# CANFD register map
Vendor: Texas Instruments
Registers are 32-bit, access per field, reset 0x0 unless marked. A register's access mark holds for its fields unless they carry their own. Offsets are as the file gives them; [hi:lo] are bit positions; lines under a group give offsets from that group; {n}, {i} and the like mark numbered series; 'fields as' and 'values as' point back to an identical list.

## CANFD (part 2 of 2) — IPXACT generated on 6/2/2017 at 11:21 by the IPXCEL-to-IPXACT Converter Script v3.1
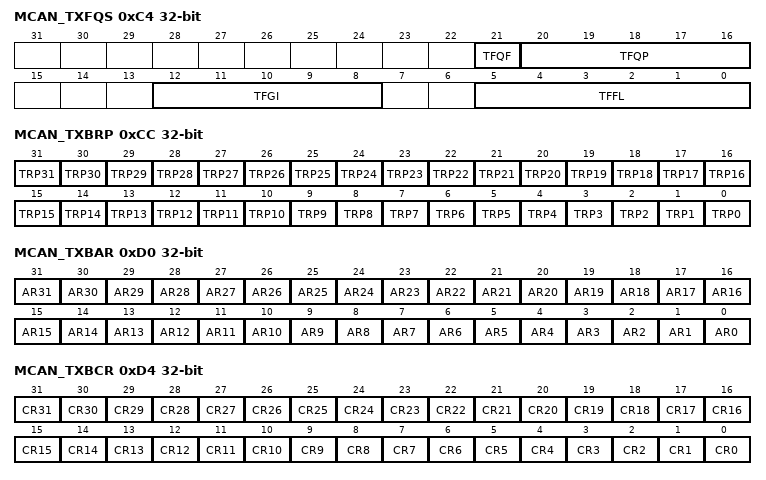
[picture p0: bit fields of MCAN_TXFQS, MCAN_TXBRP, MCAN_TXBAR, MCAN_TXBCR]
0xC4 MCAN_TXFQS ro — The Tx FIFO/Queue status is related to the pending Tx requests listed in register TXBRP. Therefore the effect of Add/Cancellation requests may be delayed due to a running Tx scan (TXBRP not yet updated).
  [21] TFQF — Tx FIFO/Queue Full 0 Tx FIFO/Queue not full 1 Tx FIFO/Queue full
  [20:16] TFQP — Tx FIFO/Queue Put Index. Tx FIFO/Queue write index pointer, range 0 to 31. Note: In case of mixed configurations where dedicated Tx Buffers are combined with a Tx FIFO or a Tx Queue, the Put and Get Indices indicate the number of the Tx Buffer starting with the first dedicated Tx Buffers. Example: For a configuration of 12 dedicated Tx Buffers and a Tx FIFO of 20 Buffers a Put Index of 15 points to the fourth buffer of the Tx FIFO.
  [12:8] TFGI — Tx FIFO Get Index. Tx FIFO read index pointer, range 0 to 31. Read as zero when Tx Queue operation is configured (TXBC.TFQM = '1'). Note: In case of mixed configurations where dedicated Tx Buffers are combined with a Tx FIFO or a Tx Queue, the Put and Get Indices indicate the number of the Tx Buffer starting with the first dedicated Tx Buffers. Example: For a configuration of 12 dedicated Tx Buffers and a Tx FIFO of 20 Buffers a Put Index of 15 points to the fourth buffer of the Tx FIFO.
  [5:0] TFFL — Tx FIFO Free Level. Number of consecutive free Tx FIFO elements starting from TFGI, range 0 to 32. Read as zero when Tx Queue operation is configured (TXBC.TFQM = '1').
0xC8 MCAN_TXESC — Configures the number of data bytes belonging to a Tx Buffer element. Data field sizes $gt; 8 bytes are intended for CAN FD operation only.
  [2:0] TBDS rw — Tx Buffer Data Field Size 000 8 byte data field 001 12 byte data field 010 16 byte data field 011 20 byte data field 100 24 byte data field 101 32 byte data field 110 48 byte data field 111 64 byte data field Note: In case the data length code DLC of a Tx Buffer element is configured to a value higher than the Tx Buffer data field size TXESC.TBDS, the bytes not defined by the Tx Buffer are transmitted as "0xCC" (padding bytes). Qualified Write is possible only with CCCR.CCE='1' and CCCR.INIT='1'.
0xCC MCAN_TXBRP ro — MCAN Tx Buffer Request Pending
  [n] TRP{n} (n=1..31) — Transmission Request Pending {n}. See description for bit 0.
  [0] TRP0 — Transmission Request Pending 0. Each Tx Buffer has its own Transmission Request Pending bit. The bits are set via register TXBAR. The bits are reset after a requested transmission has completed or has been cancelled via register TXBCR. TXBRP bits are set only for those Tx Buffers configured via TXBC. After a TXBRP bit has been set, a Tx scan is started to check for the pending Tx request with the highest priority (Tx Buffer with lowest Message ID). A cancellation request resets the corresponding transmission request pending bit of register TXBRP. In case a transmission has already been started when a cancellation is requested, this is done at the end of the transmission, regardless whether the transmission was successful or not. The cancellation request bits are reset directly after the corresponding TXBRP bit has been reset. After a cancellation has been requested, a finished cancellation is signalled via TXBCF - after successful transmission together with the corresponding TXBTO bit - when the transmission has not yet been started at the point of cancellation - when the transmission has been aborted due to lost arbitration - when an error occurred during frame transmission In DAR mode all transmissions are automatically cancelled if they are not successful. The corresponding TXBCF bit is set for all unsuccessful transmissions. 0 No transmission request pending 1 Transmission request pending Note: TXBRP bits which are set while a Tx scan is in progress are not considered during this particular Tx scan. In case a cancellation is requested for such a Tx Buffer, this Add Request is cancelled immediately, the corresponding TXBRP bit is reset.
0xD0 MCAN_TXBAR rw — MCAN Tx Buffer Add Request
  [n] AR{n} (n=1..31) — Add Request {n}. See description for bit 0.
  [0] AR0 — Add Request 0. Each Tx Buffer has its own Add Request bit. Writing a '1' will set the corresponding Add Request bit; writing a '0' has no impact. This enables the Host to set transmission requests for multiple Tx Buffers with one write to TXBAR. TXBAR bits are set only for those Tx Buffers configured via TXBC. When no Tx scan is running, the bits are reset immediately, else the bits remain set until the Tx scan process has completed. 0 No transmission request added 1 Transmission requested added Note: If an add request is applied for a Tx Buffer with pending transmission request (corresponding TXBRP bit already set), this add request is ignored. Qualified Write is possible only with CCCR.CCE='0'
0xD4 MCAN_TXBCR rw — MCAN Tx Buffer Cancellation Request
  [n] CR{n} (n=1..31) — Cancellation Request {n}. See description for bit 0.
  [0] CR0 — Cancellation Request 0. Each Tx Buffer has its own Cancellation Request bit. Writing a '1' will set the corresponding Cancellation Request bit; writing a '0' has no impact. This enables the Host to set cancellation requests for multiple Tx Buffers with one write to TXBCR. TXBCR bits are set only for those Tx Buffers configured via TXBC. The bits remain set until the corresponding bit of TXBRP is reset. 0 No cancellation pending 1 Cancellation pending Qualified Write is possible only with CCCR.CCE='0'
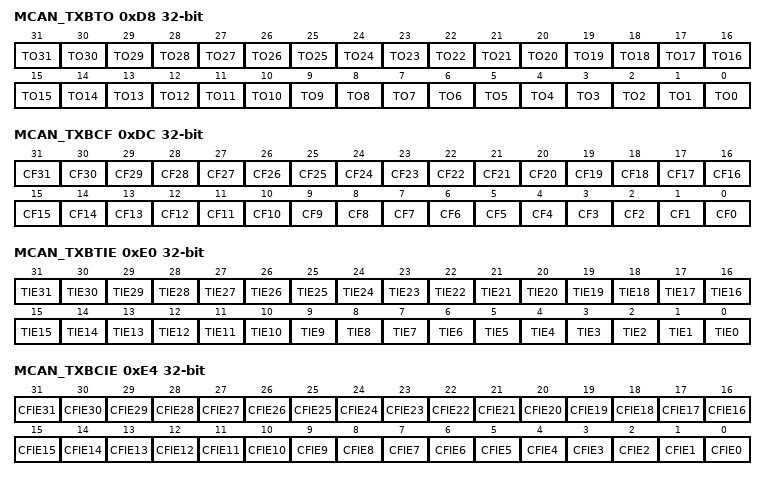
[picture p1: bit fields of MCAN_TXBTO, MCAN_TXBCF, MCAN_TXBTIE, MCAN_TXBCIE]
0xD8 MCAN_TXBTO ro — MCAN Tx Buffer Transmission Occurred
  [n] TO{n} (n=1..31) — Transmission Occurred {n}. See description for bit 0.
  [0] TO0 — Transmission Occurred 0. Each Tx Buffer has its own Transmission Occurred bit. The bits are set when the corresponding TXBRP bit is cleared after a successful transmission. The bits are reset when a new transmission is requested by writing a '1' to the corresponding bit of register TXBAR. 0 No transmission occurred 1 Transmission occurred
0xDC MCAN_TXBCF ro — MCAN Tx Buffer Cancellation Finished
  [n] CF{n} (n=1..31) — Cancellation Finished {n}. See description for bit 0.
  [0] CF0 — Cancellation Finished 0. Each Tx Buffer has its own Cancellation Finished bit. The bits are set when the corresponding TXBRP bit is cleared after a cancellation was requested via TXBCR. In case the corresponding TXBRP bit was not set at the point of cancellation, CF is set immediately. The bits are reset when a new transmission is requested by writing a '1' to the corresponding bit of register TXBAR. 0 No transmit buffer cancellation 1 Transmit buffer cancellation finished
0xE0 MCAN_TXBTIE rw — MCAN Tx Buffer Transmission Interrupt Enable
  [n] TIE{n} (n=0..31) — Transmission Interrupt Enable {n}. Each Tx Buffer has its own Transmission Interrupt Enable bit. 0 Transmission interrupt disabled 1 Transmission interrupt enable
0xE4 MCAN_TXBCIE rw — MCAN Tx Buffer Cancellation Finished Interrupt Enable
  [n] CFIE{n} (n=0..31) — Cancellation Finished Interrupt Enable {n}. Each Tx Buffer has its own Cancellation Finished Interrupt Enable bit. 0 Cancellation finished interrupt disabled 1 Cancellation finished interrupt enabled
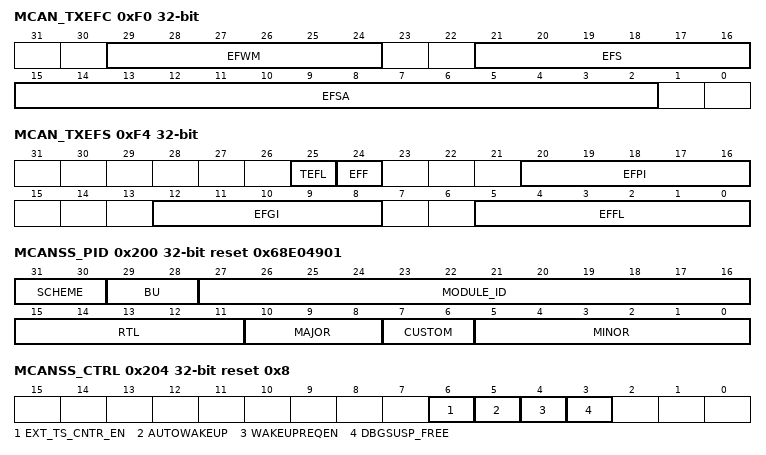
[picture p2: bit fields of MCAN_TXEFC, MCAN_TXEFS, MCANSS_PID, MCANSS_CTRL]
0xF0 MCAN_TXEFC — MCAN Tx Event FIFO Configuration
  [29:24] EFWM rw — Event FIFO Watermark 0 Watermark interrupt disabled 1-32 Level for Tx Event FIFO watermark interrupt (IR.TEFW) $gt;32 Watermark interrupt disabled
  [21:16] EFS rw — Event FIFO Size. The Tx Event FIFO elements are indexed from 0 to EFS - 1. 0 Tx Event FIFO disabled 1-32 Number of Tx Event FIFO elements $gt;32 Values greater than 32 are interpreted as 32
  [15:2] EFSA rw — Event FIFO Start Address. Start address of Tx Event FIFO in Message RAM (32-bit word address).
0xF4 MCAN_TXEFS ro — MCAN Tx Event FIFO Status
  [25] TEFL — Tx Event FIFO Element Lost. This bit is a copy of interrupt flag IR.TEFL. When IR.TEFL is reset, this bit is also reset. 0 No Tx Event FIFO element lost 1 Tx Event FIFO element lost, also set after write attempt to Tx Event FIFO of size zero.
  [24] EFF — Event FIFO Full 0 Tx Event FIFO not full 1 Tx Event FIFO full
  [20:16] EFPI — Event FIFO Put Index.Tx Event FIFO write index pointer, range 0 to 31.
  [12:8] EFGI — Event FIFO Get Index. Tx Event FIFO read index pointer, range 0 to 31.
  [5:0] EFFL — Event FIFO Fill Level. Number of elements stored in Tx Event FIFO, range 0 to 32.
0xF8 MCAN_TXEFA — MCAN Tx Event FIFO Acknowledge
  [4:0] EFAI rw — Event FIFO Acknowledge Index. After the Host has read an element or a sequence of elements from the Tx Event FIFO it has to write the index of the last element read from Tx Event FIFO to EFAI. This will set the Tx Event FIFO Get Index TXEFS.EFGI to EFAI + 1 and update the Event FIFO Fill Level TXEFS.EFFL.
0x200 MCANSS_PID ro reset 0x68E04901 — MCAN Subsystem Revision Register
  [31:30] SCHEME — PID Register Scheme
  [29:28] BU — Business Unit: 0x2 = Processors
  [27:16] MODULE_ID — Module Identification Number
  [15:11] RTL — RTL revision. Will vary depending on release
  [10:8] MAJOR — Major Revision of the MCAN Subsystem
  [7:6] CUSTOM — Custom Value
  [5:0] MINOR — Minor Revision of the MCAN Subsystem
0x204 MCANSS_CTRL reset 0x8 — MCAN Subsystem Control Register
  [6] EXT_TS_CNTR_EN rw — External Timestamp Counter Enable. When disabled, the counter is reset back to zero.While enabled, the counter keeps incrementing. 0 External timestamp counter disabled 1 External timestamp counter enabled
  [5] AUTOWAKEUP rw — Automatic Wakeup Enable. Enables the MCANSS to automatically clear the MCAN CCCR.INIT bit, fully waking the MCAN up, on an enabled wakeup request. 0 Disable the automatic write to CCCR.INIT 1 Enable the automatic write to CCCR.INIT
  [4] WAKEUPREQEN rw — Wakeup Request Enable. Enables the MCANSS to wakeup on CAN RXD activity. 0 Disable wakeup request 1 Enables wakeup request
  [3] DBGSUSP_FREE rw — Debug Suspend Free Bit. Enables debug suspend. 0 Disable debug suspend 1 Enable debug suspend
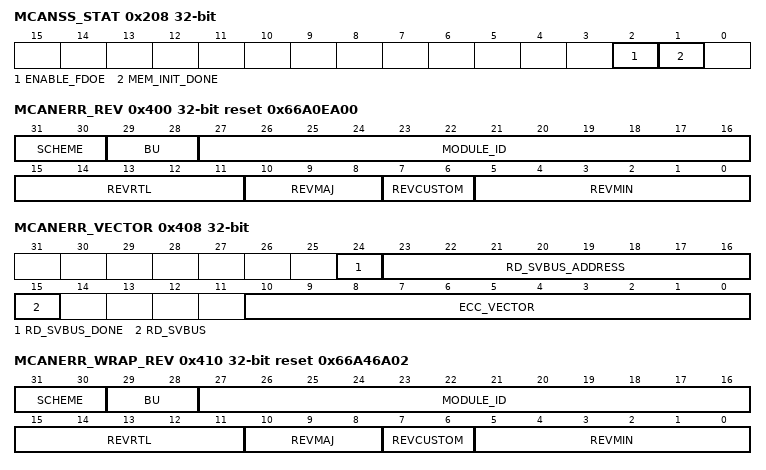
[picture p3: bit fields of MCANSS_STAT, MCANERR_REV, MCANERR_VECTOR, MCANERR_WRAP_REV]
0x208 MCANSS_STAT ro — MCAN Subsystem Status Register
  [2] ENABLE_FDOE — Flexible Datarate Operation Enable. Determines whether CAN FD operation can be enabled via the MCAN core CCCR.FDOE bit (bit 8) or if only standard CAN operation is possible with this instance of the MCAN. 0 MCAN is only capable of standard CAN communication 1 MCAN may be configured to perform CAN FD communication
  [1] MEM_INIT_DONE — Memory Initialization Done. 0 Message RAM initialization is in progress 1 Message RAM is initialized for use
0x20C MCANSS_ICS — MCAN Subsystem Interrupt Clear Shadow Register
  [0] EXT_TS_CNTR_OVFL wo — External Timestamp Counter Overflow Interrupt Status Clear. Reads always return a 0. 0 Write of '0' has no effect 1 Write of '1' clears the MCANSS_IRS.EXT_TS_CNTR_OVFL bit
0x210 MCANSS_IRS — MCAN Subsystem Interrupt Raw Satus Register
  [0] EXT_TS_CNTR_OVFL rw — External Timestamp Counter Overflow Interrupt Status. This bit is set by HW or by a SW write of '1'. To clear, use the MCANSS_ICS.EXT_TS_CNTR_OVFL bit. 0 External timestamp counter has not overflowed 1 External timestamp counter has overflowed When this bit is set to '1' by HW or SW, the MCANSS_EXT_TS_UNSERVICED_INTR_CNTR.EXT_TS_INTR_CNTR bit field will increment by 1.
0x214 MCANSS_IECS — MCAN Subsystem Interrupt Enable Clear Shadow Register
  [0] EXT_TS_CNTR_OVFL rw — External Timestamp Counter Overflow Interrupt Enable Clear. Reads always return a 0. 0 Write of '0' has no effect 1 Write of '1' clears the MCANSS_IES.EXT_TS_CNTR_OVFL bit
0x218 MCANSS_IE — MCAN Subsystem Interrupt Enable Register
  [0] EXT_TS_CNTR_OVFL rw — External Timestamp Counter Overflow Interrupt Enable. A write of '0' has no effect. A write of '1' unmasks the MCAN_IRS.EXT_EVT_CNTR_OVFLW and reflects the unmasked IRS value in MCAN_IES.EXT_TS_CNTR_OVFL
0x21C MCANSS_IES ro — MCAN Subsystem Masked Interrupt Status. It is the logical AND of IRS and IE for the respecitve bits.
  [0] EXT_TS_CNTR_OVFL — External Timestamp Counter Overflow masked interrupt status. 0 External timestamp counter overflow interrupt is cleared 1 External timestamp counter overflow interrupt is set
0x220 MCANSS_EOI — MCAN Subsystem End of Interrupt
  [7:0] EOI rw — End of Interrupt. A write to this register will clear the associated interrupt. If the unserviced interrupt counter is $gt; 1, another interrupt is generated. 0x00 External TS Interrupt is cleared 0x01 MCAN(0) interrupt is cleared 0x02 MCAN(1) interrupt is cleared Other writes are ignored.
0x224 MCANSS_EXT_TS_PRESCALER — MCAN Subsystem External Timestamp Prescaler 0
  [23:0] PRESCALER rw — External Timestamp Prescaler Reload Value. The external timestamp count rate is the host (system) clock rate divided by this value, except in the case of 0. A zero value in this bit field will act identically to a value of 0x000001.
0x228 MCANSS_EXT_TS_UNSERVICED_INTR_CNTR ro — MCAN Subsystem External Timestamp Unserviced Interrupts Counter
  [4:0] EXT_TS_INTR_CNTR — External Timestamp Counter Unserviced Rollover Interrupts. If this value is $gt; 1, an MCANSS_EOI write of '1' to bit 0 will issue another interrupt. The status of this bit field is affected by the MCANSS_IRS.EXT_TS_CNTR_OVFL bit field.
0x400 MCANERR_REV ro reset 0x66A0EA00 — MCAN Error Aggregator Revision Register
  [31:30] SCHEME — PID Register Scheme
  [29:28] BU — Business Unit: 0x2 = Processors
  [27:16] MODULE_ID — Module Identification Number
  [15:11] REVRTL — RTL revision. Will vary depending on release
  [10:8] REVMAJ — Major Revision of the Error Aggregator
  [7:6] REVCUSTOM — Custom Revision of the Error Aggregator
  [5:0] REVMIN — Minor Revision of the Error Aggregator
0x408 MCANERR_VECTOR — Each error detection and correction (EDC) controller has a bank of error registers (offsets 0x10 - 0x3B) associated with it. These registers are accessed via an internal serial bus (SVBUS). To access them through the ECC aggregator the controller ID desired must be written to the ECC_VECTOR field, together with the RD_SVBUS trigger and RD_SVBUS_ADDRESS bit field. This initiates the serial read which consummates by setting the RD_SVBUS_DONE bit. At this point the addressed register may be read by a normal CPU read of the appropriate offset address.
  [24] RD_SVBUS_DONE ro — Read Completion Flag
  [23:16] RD_SVBUS_ADDRESS rw — Read Address Offset
  [15] RD_SVBUS rw — Read Trigger
  [10:0] ECC_VECTOR rw — ECC RAM ID. Each error detection and correction (EDC) controller has a bank of error registers (offsets 0x10 - 0x3B) associated with it. These registers are accessed via an internal serial bus (SVBUS). To access them through the ECC aggregator the controller ID desired must be written to the ECC_VECTOR field, together with the RD_SVBUS trigger and RD_SVBUS_ADDRESS bit field. This initiates the serial read which consummates by setting the RD_SVBUS_DONE bit. At this point the addressed register may be read by a normal CPU read of the appropriate offset address. 0x000 Message RAM ECC controller is selected Others Reserved (do not use) Subsequent writes through the SVBUS (offsets 0x10 - 0x3B) have a delayed completion. To avoid conflicts, perform a read back of a register within this range after writing.
0x40C MCANERR_STAT ro reset 0x2 — MCAN Error Misc Status
  [10:0] NUM_RAMS — Number of RAMs. Number of ECC RAMs serviced by the aggregator.
0x410 MCANERR_WRAP_REV ro reset 0x66A46A02 — This register is accessed through the ECC aggregator via an internal serial bus. To access, the appropriate procedure must be first followed in the MCAN ECC Vector Register.
  fields as MCANERR_REV
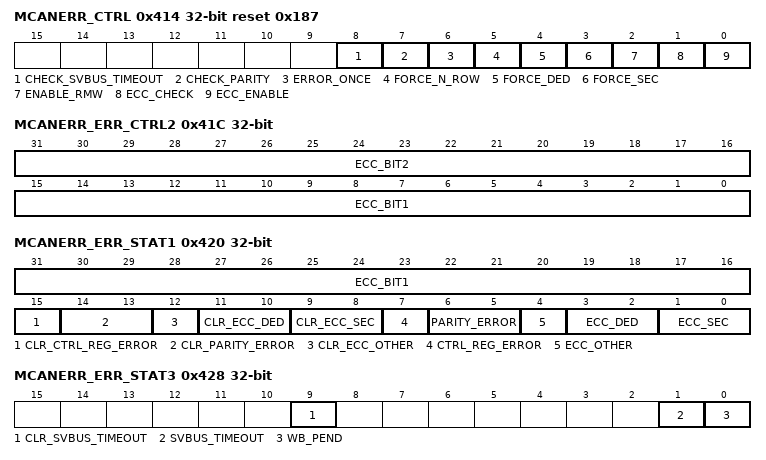
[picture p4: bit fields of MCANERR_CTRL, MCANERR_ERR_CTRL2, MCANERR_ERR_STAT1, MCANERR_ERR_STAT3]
0x414 MCANERR_CTRL reset 0x187 — This register is accessed through the ECC aggregator via an internal serial bus. To access, the appropriate procedure must be first followed in the MCAN ECC Vector Register.
  [8] CHECK_SVBUS_TIMEOUT rw — Enables Serial VBUS timeout mechanism
  [7] CHECK_PARITY rw — Enables parity checking on internal data
  [6] ERROR_ONCE rw — If this bit is set, the FORCE_SEC/FORCE_DED will inject an error to the specified row only once. The FORCE_SEC bit will be cleared once a writeback happens. If writeback is not enabled, this error will be cleared the cycle following the read when the data is corrected. For double-bit errors, the FORCE_DED bit will be cleared the cycle following the double-bit error. Any subsequent reads will not force an error.
  [5] FORCE_N_ROW rw — Enable single/double-bit error on the next RAM read, regardless of the MCANERR_ERR_CTRL1.ECC_ROW setting. For write through mode, this applies to writes as well as reads.
  [4] FORCE_DED rw — Force double-bit error. Cleared the cycle following the error if ERROR_ONCE is asserted. For write through mode, this applies to writes as well as reads. MCANERR_ERR_CTRL1 and MCANERR_ERR_CTRL2 should be configured prior to setting this bit.
  [3] FORCE_SEC rw — Force single-bit error. Cleared on a writeback or the cycle following the error if ERROR_ONCE is asserted. For write through mode, this applies to writes as well as reads. MCANERR_ERR_CTRL1 and MCANERR_ERR_CTRL2 should be configured prior to setting this bit.
  [2] ENABLE_RMW rw — Enable read-modify-write on partial word writes
  [1] ECC_CHECK rw — Enable ECC Check. ECC is completely bypassed if both ECC_ENABLE and ECC_CHECK are '0'.
  [0] ECC_ENABLE rw — Enable ECC Generation
0x418 MCANERR_ERR_CTRL1 rw — This register is accessed through the ECC aggregator via an internal serial bus. To access, the appropriate procedure must be first followed in the MCAN ECC Vector Register.
  [31:0] ECC_ROW — Row address where FORCE_SEC or FORCE_DED needs to be applied. This is ignored if FORCE_N_ROW is set.
0x41C MCANERR_ERR_CTRL2 rw — This register is accessed through the ECC aggregator via an internal serial bus. To access, the appropriate procedure must be first followed in the MCAN ECC Vector Register.
  [31:16] ECC_BIT2 — Second column/data bit that needs to be flipped when FORCE_DED is set
  [15:0] ECC_BIT1 — Column/Data bit that needs to be flipped when FORCE_SEC or FORCE_DED is set
0x420 MCANERR_ERR_STAT1 — This register is accessed through the ECC aggregator via an internal serial bus. To access, the appropriate procedure must be first followed in the MCAN ECC Vector Register.
  [31:16] ECC_BIT1 ro — ECC Error Bit Position. Indicates the bit position in the RAM data that is in error on an SEC error. Only valid on an SEC error. 0 Bit 0 is in error 1 Bit 1 is in error 2 Bit 2 is in error 3 Bit 3 is in error ... 31 Bit 31 is in error $gt;32 Invalid
  [15] CLR_CTRL_REG_ERROR rw — Writing a '1' clears the CTRL_REG_ERROR bit
  [14:13] CLR_PARITY_ERROR rw — Clear Parity Error. A write of a non-zero value to this bit field decrements the PARITY_ERROR bit field by the value provided.
  [12] CLR_ECC_OTHER rw — Writing a '1' clears the ECC_OTHER bit.
  [11:10] CLR_ECC_DED rw — Clear ECC_DED. A write of a non-zero value to this bit field decrements the ECC_DED bit field by the value provided.
  [9:8] CLR_ECC_SEC rw — Clear ECC_SEC. A write of a non-zero value to this bit field decrements the ECC_SEC bit field by the value provided.
  [7] CTRL_REG_ERROR rw — Control Register Error. A bit field in the control register is in an ambiguous state. This means that the redundancy registers have detected a state where not all values are the same and has defaulted to the reset state. S/W needs to re-write these registers to a known state. A write of 1 will set this interrupt flag.
  [6:5] PARITY_ERROR rw — Parity Error Status. A 2-bit saturating counter of the number of parity errors that have occurred since last cleared. 0 No parity error detected 1 One parity error was detected 2 Two parity errors were detected 3 Three parity errors were detected A write of a non-zero value to this bit field increments it by the value provided.
  [4] ECC_OTHER rw — SEC While Writeback Error Status 0 No SEC error while writeback pending 1 Indicates that successive single-bit errors have occurred while a writeback is still pending
  [3:2] ECC_DED rw — Double Bit Error Detected Status. A 2-bit saturating counter of the number of DED errors that have occurred since last cleared. 0 No double-bit error detected 1 One double-bit error was detected 2 Two double-bit errors were detected 3 Three double-bit errors were detected A write of a non-zero value to this bit field increments it by the value provided.
  [1:0] ECC_SEC rw — Single Bit Error Corrected Status. A 2-bit saturating counter of the number of SEC errors that have occurred since last cleared. 0 No single-bit error detected 1 One single-bit error was detected and corrected 2 Two single-bit errors were detected and corrected 3 Three single-bit errors were detected and corrected A write of a non-zero value to this bit field increments it by the value provided.
0x424 MCANERR_ERR_STAT2 ro — This register is accessed through the ECC aggregator via an internal serial bus. To access, the appropriate procedure must be first followed in the MCAN ECC Vector Register.
  [31:0] ECC_ROW — Indicates the row address where the single or double-bit error occurred. This value is address offset/4.
0x428 MCANERR_ERR_STAT3 — This register is accessed through the ECC aggregator via an internal serial bus. To access, the appropriate procedure must be first followed in the MCAN ECC Vector Register.
  [9] CLR_SVBUS_TIMEOUT rw — Write 1 to clear the Serial VBUS Timeout Flag
  [1] SVBUS_TIMEOUT rw — Serial VBUS Timeout Flag. Write 1 to set.
  [0] WB_PEND ro — Delayed Write Back Pending Status 0 No write back pending 1 An ECC data correction write back is pending
0x43C MCANERR_SEC_EOI — MCAN Single Error Corrected End of Interrupt Register
  [0] EOI_WR rw — Write to this register indicates that software has acknowledged the pending interrupt and the next interrupt can be sent to the host. Note that a write to the MCANERR_ERR_STAT1.CLR_ECC_SEC goes through the SVBUS and has a delayed completion. To avoid an additional interrupt, read the MCANERR_ERR_STAT1 register back prior to writing to this bit field.
0x440 MCANERR_SEC_STATUS — MCAN Single Error Corrected Interrupt Status Register
  [0] MSGMEM_PEND rw — Message RAM SEC Interrupt Pending 0 No SEC interrupt is pending 1 SEC interrupt is pending
0x480 MCANERR_SEC_ENABLE_SET — MCAN Single Error Corrected Interrupt Enable Set Register
  [0] MSGMEM_ENABLE_SET rw — Message RAM SEC Interrupt Pending Enable Set. Writing a 1 to this bit enables the Message RAM SEC error interrupts. Writing a 0 has no effect. Reads return the corresponding enable bit's current value.
0x4C0 MCANERR_SEC_ENABLE_CLR — MCAN Single Error Corrected Interrupt Enable Clear Register
  [0] MSGMEM_ENABLE_CLR rw — Message RAM SEC Interrupt Pending Enable Clear. Writing a 1 to this bit disables the Message RAM SEC error interrupts. Writing a 0 has no effect. Reads return the corresponding enable bit's current value.
0x53C MCANERR_DED_EOI — MCAN Double Error Detected End of Interrupt Register
  [0] EOI_WR rw — Write to this register indicates that software has acknowledged the pending interrupt and the next interrupt can be sent to the host. Note that a write to the MCANERR_ERR_STAT1.CLR_ECC_DED goes through the SVBUS and has a delayed completion. To avoid an additional interrupt, read the MCANERR_ERR_STAT1 register back prior to writing to this bit field.
0x540 MCANERR_DED_STATUS — MCAN Double Error Detected Interrupt Status Register
  [0] MSGMEM_PEND rw — Message RAM DED Interrupt Pending 0 No DED interrupt is pending 1 DED interrupt is pending
0x580 MCANERR_DED_ENABLE_SET — MCAN Double Error Detected Interrupt Enable Set Register
  [0] MSGMEM_ENABLE_SET rw — Message RAM DED Interrupt Pending Enable Set. Writing a 1 to this bit enables the Message RAM DED error interrupts. Writing a 0 has no effect. Reads return the corresponding enable bit's current value.
0x5C0 MCANERR_DED_ENABLE_CLR — MCAN Double Error Detected Interrupt Enable Clear Register
  [0] MSGMEM_ENABLE_CLR rw — Message RAM DED Interrupt Pending Enable Clear. Writing a 1 to this bit disables the Message RAM DED error interrupts. Writing a 0 has no effect. Reads return the corresponding enable bit's current value.
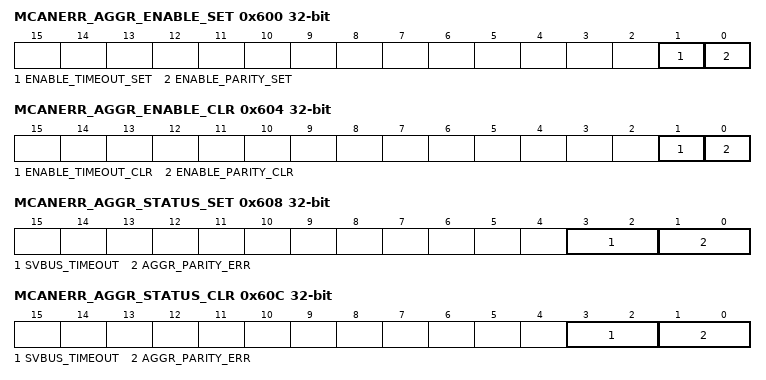
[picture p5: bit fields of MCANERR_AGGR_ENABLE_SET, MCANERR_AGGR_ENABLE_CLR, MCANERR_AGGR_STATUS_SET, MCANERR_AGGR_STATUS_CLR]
0x600 MCANERR_AGGR_ENABLE_SET — MCAN Error Aggregator Enable Set Register
  [1] ENABLE_TIMEOUT_SET rw — Write 1 to enable timeout errors. Reads return the corresponding enable bit's current value.
  [0] ENABLE_PARITY_SET rw — Write 1 to enable parity errors. Reads return the corresponding enable bit's current value.
0x604 MCANERR_AGGR_ENABLE_CLR — MCAN Error Aggregator Enable Clear Register
  [1] ENABLE_TIMEOUT_CLR rw — Write 1 to disable timeout errors. Reads return the corresponding enable bit's current value.
  [0] ENABLE_PARITY_CLR rw — Write 1 to disable parity errors. Reads return the corresponding enable bit's current value.
0x608 MCANERR_AGGR_STATUS_SET — MCAN Error Aggregator Status Set Register
  [3:2] SVBUS_TIMEOUT rw — Aggregator Serial VBUS Timeout Error Status 2-bit saturating counter of the number of SVBUS timeout errors that have occurred since last cleared. 0 No timeout errors have occurred 1 One timeout error has occurred 2 Two timeout errors have occurred 3 Three timeout errors have occurred A write of a non-zero value to this bit field increments it by the value provided.
  [1:0] AGGR_PARITY_ERR rw — Aggregator Parity Error Status 2-bit saturating counter of the number of parity errors that have occurred since last cleared. 0 No parity errors have occurred 1 One parity error has occurred 2 Two parity errors have occurred 3 Three parity errors have occurred A write of a non-zero value to this bit field increments it by the value provided.
0x60C MCANERR_AGGR_STATUS_CLR — MCAN Error Aggregator Status Clear Register
  [3:2] SVBUS_TIMEOUT rw — Aggregator Serial VBUS Timeout Error Status 2-bit saturating counter of the number of SVBUS timeout errors that have occurred since last cleared. 0 No timeout errors have occurred 1 One timeout error has occurred 2 Two timeout errors have occurred 3 Three timeout errors have occurred A write of a non-zero value to this bit field decrements it by the value provided.
  [1:0] AGGR_PARITY_ERR rw — Aggregator Parity Error Status 2-bit saturating counter of the number of parity errors that have occurred since last cleared. 0 No parity errors have occurred 1 One parity error has occurred 2 Two parity errors have occurred 3 Three parity errors have occurred A write of a non-zero value to this bit field decrements it by the value provided.
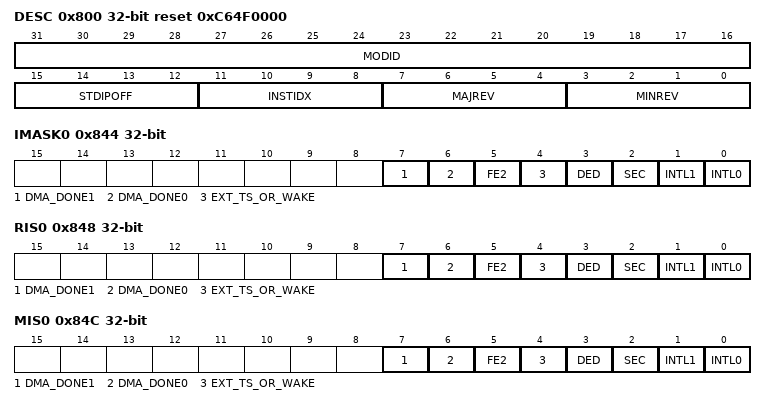
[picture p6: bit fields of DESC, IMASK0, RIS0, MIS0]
0x800 DESC ro reset 0xC64F0000 — Description Shows module version and module ID
  [31:16] MODID — Module identifier MODID[15:0]. Used to uniquely identify this IP.
  [15:12] STDIPOFF — 64 B standard IP MMR block (beginning with aggregated IRQ registers) 0: STDIP MMRs do not exist 1:15: These MMRs begin at offset 64*STDIPOFF from IP base address
  [11:8] INSTIDX — If multiple instances of IP exists in SOC, this field can identify the instance number 0-15
  [7:4] MAJREV — Major revision of IP 0-15
  [3:0] MINREV — Minor revision of IP 0-15 (typically revision is 1.0 for a verified new IP)
0x844 IMASK0 — Interrupt Mask. If a bit is set, then corresponding interrupt is un-masked. Un-masking the interrupt causes the raw interrupt to be visible in IIDX, as well as MIS.
  [all] fields
    1=SET (Set Interrrupt Mask); 0=CLR (Clear Interrupt Mask)
  [7] DMA_DONE1 rw — DMA DONE channel 1 interrupt mask for MIS0.
  [6] DMA_DONE0 rw — DMA DONE channel 0 interrupt mask for MIS0.
  [5] FE2 rw — Filter event 2 interrupt mask for MIS0.
  [4] EXT_TS_OR_WAKE rw — External Timestamp Counter Overflow interrupt mask for MIS0.
  [3] DED rw — Message RAM DED interrupt mask for MIS0.
  [2] SEC rw — Message RAM SEC interrupt mask for MIS0.
  [1] INTL1 rw — MCAN Interrupt Line1 mask for MIS0.
  [0] INTL0 rw — MCAN Interrupt Line 0 mask for MIS0.
0x848 RIS0 ro — Raw interrupt status. Reflects all pending interrupts, regardless of masking. The RIS0 register allows the user to implement a poll scheme. A flag set in this register can be cleared by writing 1 to the ICLR register bit even if the corresponding IMASK bit is not enabled.
  [all] fields
    1=SET (Interrupt occured); 0=CLR (Interrupt did not occur)
  [7] DMA_DONE1 — Raw Interrupt Status for DMA Done interrupt of DMA channel1.
  [6] DMA_DONE0 — Raw Interrupt Status for DMA Done interrupt of DMA channel0.
  [5] FE2 — Raw Interrupt Status for Filter Event 2 interrupt.
  [4] EXT_TS_OR_WAKE — Raw Interrupt Status for External Timestamp Counter Overflow interrupt.
  [3] DED — Raw Interrupt Status for Message RAM DED interrupt.
  [2] SEC — Raw Interrupt status for Message RAM SEC interrupt.
  [1] INTL1 — Raw Interrupt status for MCAN Interrupt Line 1.
  [0] INTL0 — Raw Interrupt status for MCAN Interrupt Line 0.
0x84C MIS0 ro — Masked interrupt status. This is an AND of the IMASK and RIS registers.
  [all] fields
    1=SET (Interrupt occured); 0=CLR (Interrupt did not occur)
  [7] DMA_DONE1 — Mask interrupt status for DMA DONE interrupt of DMA channel1.
  [6] DMA_DONE0 — Mask interrupt status for DMA DONE interrupt of DMA channel0.
  [5] FE2 — Masked Interrupt status for Filter event 2 interrupt.
  [4] EXT_TS_OR_WAKE — Masked Interrupt status for External Timestamp counter Overflow interrupt.
  [3] DED — Masked Interrupt status for Message RAM DED interrupt.
  [2] SEC — Masked Interrupt status for Message RAM SEC interrupt.
  [1] INTL1 — Mask interrupt status for MCAN Interrupt Line 1.
  [0] INTL0 — Mask interrupt status for MCAN Interrupt Line 0.
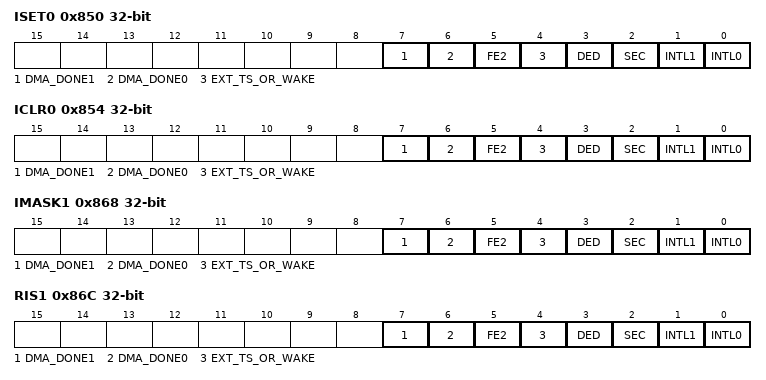
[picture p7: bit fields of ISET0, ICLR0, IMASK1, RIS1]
0x850 ISET0 — Interrupt set. Allows interrupts to be set by software (useful in diagnostics and safety checks). Writing a 1 to a bit in ISET0 will set the event and therefore the related RIS bit also gets set. If the interrupt is enabled through the mask, then the corresponding MIS bit is also set.
  [all] fields
    1=SET (Sets interrupt); 0=NO_EFFECT (Writing 0 has no effect)
  [7] DMA_DONE1 wo — Sets DMA DONE for DMA channel 1 interrupt in RIS0.
  [6] DMA_DONE0 wo — Sets DMA DONE for DMA channel 0 interrupt in RIS0.
  [5] FE2 wo — Sets Filter event 2 interrupt in RIS0.
  [4] EXT_TS_OR_WAKE wo — Sets External Time stamp counter Overflow interrupt in RIS0.
  [3] DED wo — Sets Message RAM DED interrupt in RIS0.
  [2] SEC wo — Sets Message RAM SEC interrupt in RIS0.
  [1] INTL1 wo — Sets MCAN Interrupt Line 1 interrupt in RIS0.
  [0] INTL0 wo — Sets MCAN Interrupt Line 0 interrupt in RIS0.
0x854 ICLR0 — Interrupt clear. Write a 1 to clear corresponding Interrupt.
  [all] fields
    1=CLR (Clears the Event); 0=NO_EFFECT (Writing 0 has no effect)
  [7] DMA_DONE1 wo — Clears DMA DONE interrupt for DMA channel 1 in RIS0.
  [6] DMA_DONE0 wo — Clears DMA DONE interrupt for DMA channel 0 in RIS0.
  [5] FE2 wo — Clears Filter Event 2 interrupt in RIS0.
  [4] EXT_TS_OR_WAKE wo — Clears External Time stamp counter Overflow in RIS0.
  [3] DED wo — Clears Message RAM DED interrupt in RIS0.
  [2] SEC wo — Clears Message RAM SEC interrupt in RIS0.
  [1] INTL1 wo — Clears MCAN Interrupt Line 1 interrupt in RIS0.
  [0] INTL0 wo — Clears MCAN Interrupt Line 0 interrupt in RIS0.
0x864 DTB — Digital Test Bus. This register is used to bring out some internal signals of the peripheral on digital test bus (DTB).
  [2:0] SEL rw — This bit field is used to select DTB mux digital output signals.
    {v}=GRP{v} (Selects test group {v}) (v=1..7); 0=DISABLE (DTB output from peripheral is 0x0.)
0x868 IMASK1 — Interrupt Mask. If a bit is set, then corresponding interrupt is un-masked. Un-masking the interrupt causes the raw interrupt to be visible in IIDX, as well as MIS.
  [all] fields
    1=SET (Set Interrrupt Mask); 0=CLR (Clear Interrupt Mask)
  [7] DMA_DONE1 rw — DMA DONE channel 1 interrupt mask for MIS1.
  [6] DMA_DONE0 rw — DMA DONE channel 0 interrupt mask for MIS1.
  [5] FE2 rw — Filter event 2 interrupt mask for MIS1.
  [4] EXT_TS_OR_WAKE rw — External Timestamp Counter Overflow interrupt mask for MIS1.
  [3] DED rw — Message RAM DED interrupt mask for MIS1.
  [2] SEC rw — Message RAM SEC interrupt mask for MIS1.
  [1] INTL1 rw — MCAN Interrupt Line1 mask for MIS1.
  [0] INTL0 rw — MCAN Interrupt Line 0 mask for MIS1.
0x86C RIS1 ro — Raw interrupt status. Reflects all pending interrupts, regardless of masking. The RIS0 register allows the user to implement a poll scheme. A flag set in this register can be cleared by writing 1 to the ICLR register bit even if the corresponding IMASK bit is not enabled.
  fields as RIS0
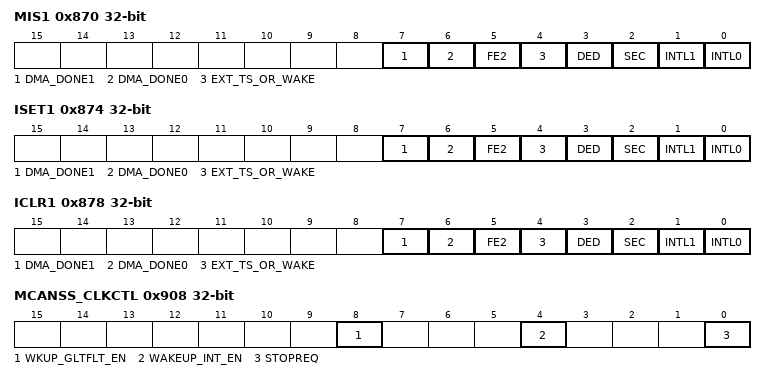
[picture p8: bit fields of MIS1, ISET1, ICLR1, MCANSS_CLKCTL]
0x870 MIS1 ro — Masked interrupt status. This is an AND of the IMASK and RIS registers.
  fields as MIS0
0x874 ISET1 — Interrupt set. Allows interrupts to be set by software (useful in diagnostics and safety checks). Writing a 1 to a bit in ISET0 will set the event and therefore the related RIS bit also gets set. If the interrupt is enabled through the mask, then the corresponding MIS bit is also set.
  [all] fields
    values as the fields of ISET0
  [7] DMA_DONE1 wo — Sets DMA DONE for DMA channel 1 interrupt in RIS1.
  [6] DMA_DONE0 wo — Sets DMA DONE for DMA channel 0 interrupt in RIS1.
  [5] FE2 wo — Sets Filter event 2 interrupt in RIS1.
  [4] EXT_TS_OR_WAKE wo — Sets External Time stamp counter Overflow interrupt in RIS1.
  [3] DED wo — Sets Message RAM DED interrupt in RIS1.
  [2] SEC wo — Sets Message RAM SEC interrupt in RIS1.
  [1] INTL1 wo — Sets MCAN Interrupt Line 1 interrupt in RIS1.
  [0] INTL0 wo — Sets MCAN Interrupt Line 0 interrupt in RIS1.
0x878 ICLR1 — Interrupt clear. Write a 1 to clear corresponding Interrupt.
  [all] fields
    values as the fields of ICLR0
  [7] DMA_DONE1 wo — Clears DMA DONE interrupt for DMA channel 1 in RIS1.
  [6] DMA_DONE0 wo — Clears DMA DONE interrupt for DMA channel 0 in RIS1.
  [5] FE2 wo — Clears Filter Event 2 interrupt in RIS1.
  [4] EXT_TS_OR_WAKE wo — Clears External Time stamp counter Overflow in RIS1.
  [3] DED wo — Clears Message RAM DED interrupt in RIS1.
  [2] SEC wo — Clears Message RAM SEC interrupt in RIS1.
  [1] INTL1 wo — Clears MCAN Interrupt Line 0 interrupt in RIS1.
  [0] INTL0 wo — Clears MCAN Interrupt Line 0 interrupt in RIS1.
0x904 MCANSS_CLKDIV — Needs to go to the Management apperture once available
  [1:0] RATIO rw — Clock divide ratio specification. Enables configuring clock divide settings for the MCAN functional clock input to the MCAN-SS.
    2=DIV_BY_4_ (Divides input clock by 4); 1=DIV_BY_2_ (Divides input clock by 2); 0=DIV_BY_1_ (Divides input clock by 1)
0x908 MCANSS_CLKCTL — MCANSS clock stop control MMR. $lt;Internal note$gt; Bus clock for the Dragon wrapper MMRs (including this MMR) is not gated by this register.
  [8] WKUP_GLTFLT_EN rw — Setting this bit enables the glitch filter on MCAN RXD input, which wakes up the MCAN controller to exit clock gating.
    1=ENABLE (Enable glitch filter enable on RXD input when MCAN is in clock stop mode (waiting for event on RXD input for clock stop wakeup).); 0=DISABLE (Disable glitch filter enable on RXD input when MCAN is in clock stop mode (waiting for event on RXD input for clock stop wakeup).)
  [4] WAKEUP_INT_EN rw — This bit contols enabling or disabling the MCAN IP clock stop wakeup interrupt (when MCANSS_CTRL.WAKEUPREQEN wakeup request is enabled to wakeup MCAN IP upon CAN RXD activity)
    1=ENABLE (Enable MCAN IP clock stop wakeup interrupt); 0=DISABLE (Disable MCAN IP clock stop wakeup interrupt)
  [0] STOPREQ rw — This bit is used to enable/disable MCAN clock (both host clock and functional clock) gating request. Note: This bit can be reset by HW by Clock-Stop Wake-up via CAN RX Activity. See spec for more details.
    1=ENABLE (Enable MCAN-SS clock stop request); 0=DISABLE (Disable MCAN-SS clock stop request)
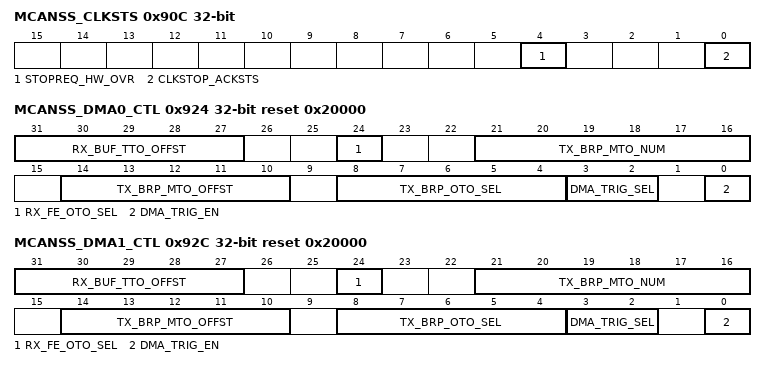
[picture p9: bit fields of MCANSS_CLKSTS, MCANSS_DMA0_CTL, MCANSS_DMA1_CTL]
0x90C MCANSS_CLKSTS ro — MCANSS clock stop status register to indicate status of clock stop mechanism
  [4] STOPREQ_HW_OVR — MCANSS clock stop HW override status bit. This bit indicates when the MCANSS_CLKCTL.STOPREQ bit has been cleared by HW when a clock-stop wake-up event via CAN RX activity is trigged.
    1=SET (MCANSS_CLKCTL.STOPREQ bit has been cleared by HW.); 0=RESET (MCANSS_CLKCTL.STOPREQ bit has not been cleared by HW.)
  [0] CLKSTOP_ACKSTS — Clock stop acknowledge status from MCAN IP
    1=SET (MCAN-SS may be clock gated by stopping both the CAN host and functional clocks.); 0=RESET (No clock stop acknowledged.)
0x924 MCANSS_DMA0_CTL reset 0x20000 — MCANSS fixed DMA0 control and configuration register
  [31:27] RX_BUF_TTO_OFFST rw — Indicates the Rx-buffer (index x) to be mapped to FE_0 (FE001) and automatically maps and Rx buffer (index x+1) to FE_1 (FE010) Valid range: Rxbuffer (0) to Rxbuffer (30)
    30=MAX (Maximum index value: 30 Note: RX_FE_TTO_SEL Rx buffer index selection for FE01 cannot be 31, as Rxbuffer (index +1) maps to 32, which requires updating NDAT1 and NDAT2 value, which is not supported.); 0=MIN (Minimum index value: 0)
  [24] RX_FE_OTO_SEL rw — RX_FE_OTO_SEL is used to select the MCAN RX buffer filter event signal mapped to trigger fixed MCANSS DMA channel trigger
    1=FE_1 (Filter Event 1); 0=FE_0 (Filter Event 0)
  [21:16] TX_BRP_MTO_NUM rw — Number of TX buffer request pending (BRP) signals for multi-to-one DMA trigger mapping sequence, starting from the buffer offset number selected by TX_BRP_MTO_OFFST bits
    32=MAX (Max number for TX BRP multi-to-one DMA trigger mapping sequence is 32); 2=MIN (Min number for TX BRP multi-to-one DMA trigger mapping sequence is 2)
  [14:10] TX_BRP_MTO_OFFST rw — TX_BRP_MTO_OFFST selects the Tx buffer offset number for the multi-to-one round robin DMA trigger mode.
    {v}=TX_BRP_{v} (TX Buffer Request Pending {v}) (v=0..31)
  [8:4] TX_BRP_OTO_SEL rw — TX_BRP_OTO_SEL is used to select the MCAN TX buffer request pending (BRP) signal mapped to trigger fixed MCANSS DMA channel trigger
    {v}=TX_BRP_{v} (TX Buffer Request Pending {v}) (v=0..31)
  [3:2] DMA_TRIG_SEL rw — DMA trigger select bits used to select between MCAN TX one-to-one mapping, MCAN TX multi-to-one round robin mapping and MCAN Rx one-to-one mapping options
    3=RX_TTO_TRIG (Rx buffer two-to-one DMA trigger); 2=RX_OTO_TRIG (MCAN RX Buffer one-to-one Tx BRP (buffer request pending) trigger to DMA channel select); 1=TX_MTO_TRIG (MCAN TX Buffer multi-to-one round robin, Tx BRP (buffer request pending) triggers to DMA channel select); 0=TX_OTO_TRIG (MCAN TX Buffer one-to-one Tx BRP (buffer request pending) trigger to DMA channel select)
  [0] DMA_TRIG_EN rw — DMA_TRIG_EN is used to enable/disable MCAN RX, TX triggers to MCANSS fixed DMA channel. $lt;Note to design$gt; check if this bit is needed depending on if similar functionality is enabled in the EXT_DMA aperture.
    1=ENABLE (MCANSS fixed DMA channel trigger is enabled.); 0=DISABLE (MCANSS fixed DMA channel trigger is disabled.)
0x92C MCANSS_DMA1_CTL reset 0x20000 — MCANSS fixed DMA1 control and configuration register
  [31:27] RX_BUF_TTO_OFFST rw — Indicates the Rx-buffer (index x) to be mapped to FE_0 (FE001) and automatically maps and Rx buffer (index x+1) to FE_1 (FE010) Valid range: Rxbuffer (0) to Rxbuffer (30)
    values as MCANSS_DMA0_CTL.RX_BUF_TTO_OFFST
  [24] RX_FE_OTO_SEL rw — RX_FE_OTO_SEL is used to select the MCAN RX buffer filter event signal mapped to trigger fixed MCANSS DMA channel trigger
    1=FE_1 (Filter Event 1); 0=FE_0 (Filter Event 0)
  [21:16] TX_BRP_MTO_NUM rw — Number of TX buffer request pending (BRP) signals for multi-to-one DMA trigger mapping sequence, starting from the buffer offset number selected by TX_BRP_MTO_OFFST bits
    values as MCANSS_DMA0_CTL.TX_BRP_MTO_NUM
  [14:10] TX_BRP_MTO_OFFST rw — TX_BRP_MTO_OFFST selects the Tx buffer offset number for the multi-to-one round robin DMA trigger mode.
    {v}=TX_BRP_{v} (TX Buffer Request Pending {v}) (v=0..31)
  [8:4] TX_BRP_OTO_SEL rw — TX_BRP_OTO_SEL is used to select the MCAN TX buffer request pending (BRP) signal mapped to trigger fixed MCANSS DMA channel trigger
    {v}=TX_BRP_{v} (TX Buffer Request Pending {v}) (v=0..31)
  [3:2] DMA_TRIG_SEL rw — DMA trigger select bits used to select between MCAN TX one-to-one mapping, MCAN TX multi-to-one round robin mapping and MCAN Rx one-to-one mapping options
    3=RX_TTO_TRIG (Rx buffer two-to-one DMA trigger); 2=RX_OTO_TRIG (MCAN RX Buffer one-to-one Tx BRP (buffer request pending) trigger to DMA channel select); 1=TX_MTO_TRIG (MCAN TX Buffer multi-to-one round robin Tx BRP (buffer request pending) triggers to DMA channel select); 0=TX_OTO_TRIG (MCAN TX Buffer one-to-one Tx BRP (buffer request pending) trigger to DMA channel select)
  [0] DMA_TRIG_EN rw — DMA_TRIG_EN is used to enable/disable MCAN RX, TX triggers to MCANSS fixed DMA channel. $lt;Note to design$gt; check if this bit is needed depending on if similar functionality is enabled in the EXT_DMA aperture.
    values as MCANSS_DMA0_CTL.DMA_TRIG_EN
0x938 RXDMA_TTO_FE0_BA — Rx buffer (index x) base address. $lt;Internal: Absolute address within MCAN IP: 0x7938$gt; Applicable to Rx buffer DMA two-to-one mode mapped to FE001 trigger: $gt;$gt; LS bits 0:1 in this MMR are reserved and read as '0' as the MCAN SRAM is 4 byte data addressable. $gt;$gt; Index x is selected using MCANSS_DMAn_CTL.RX_FE_TTO_SEL bits.
  [14:2] BASE_ADDR rw — FE0 Rx Buf x Base adddress (14:2). Address should be compited based on the 14-bit RBSA (Rx buffer start address) + offset (depending on Rx buffer element index value and data length code (DLC) for all the buffer elements before the Rx buffer element (x))
    0x1FFF=MAX (Max address offset within MCANSS SRAM: 0x1fff); 0=MIN (Min address offset within MCANSS SRAM: 0x0)
0x948 RXDMA_TTO_FE1_BA — Rx buffer (index x+1) base address $lt;Internal: Absolute address within MCAN IP: 0x7948$gt; Applicable to Rx buffer DMA two-to-one mode mapped to FE010 trigger: $gt;$gt; LS bits 0:1 in this MMR are reserved and read as '0' as the MCAN SRAM is 4 byte data addressable. $gt;$gt; Index x is selected using MCANSS_DMAn_CTL.RX_FE_TTO_SEL bits.
  [14:2] BASE_ADDR rw — FE010 Rx Buf x Base adddress (14:2). Address should be compited based on the 14-bit RBSA (Rx buffer start address) + offset (depending on Rx buffer element index value and data length code (DLC) for all the buffer elements before the Rx buffer element (x+1))
    values as RXDMA_TTO_FE0_BA.BASE_ADDR
0x950 RXDMA_TTO_NDAT1 rw — Rx Buffer two-to-one DMA mode, hardware NDAT1 value register. The address of this register is programmed as the DMA source address register for moving NDAT1 value during DMA operation. This register is automatically updated on the fly depending on FE001/FE010 (Rxbuf(x)/Rxbuf(x+1)) ongoing transfer.
  [31:0] NDAT1_VAL — NDAT1 value to be programmed onto MCAN.NDAT1 MMR. Automatically updated by HW.
    0x80000000=MAX (max value = (bit 31 set) = 0x80000000); 0=MIN (Min value = 0x0 (not bits set))
